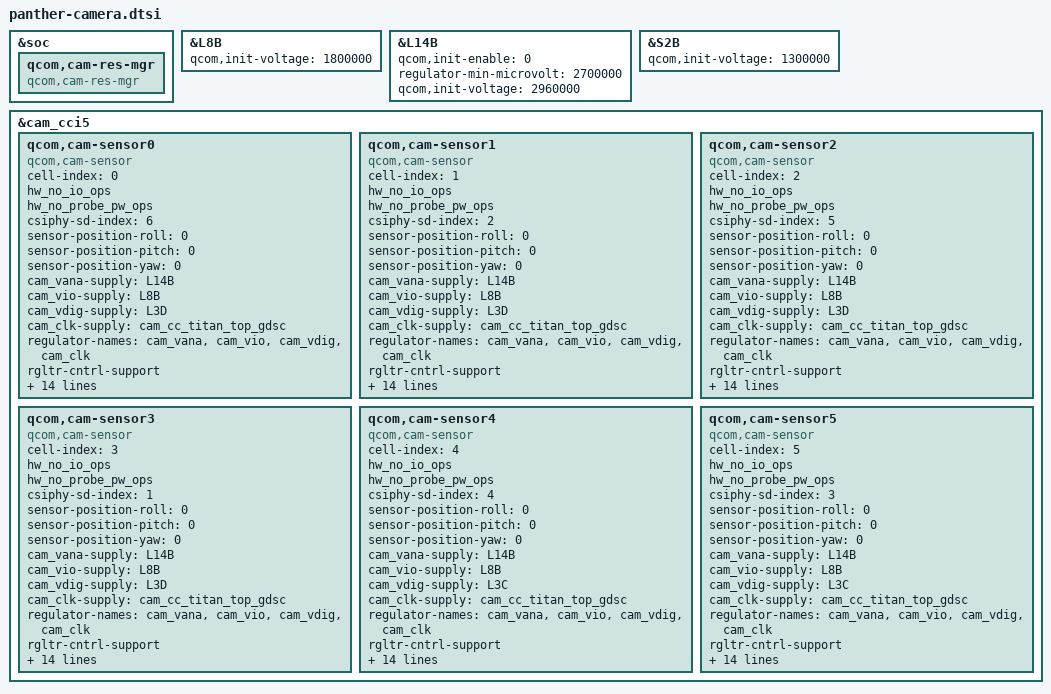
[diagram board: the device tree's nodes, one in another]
// SPDX-License-Identifier: GPL-2.0

#include <dt-bindings/camera/msm-camera.h>
#include <dt-bindings/clock/qcom,camcc-anorak.h>

&soc {
	qcom,cam-res-mgr {
		compatible = "qcom,cam-res-mgr";
		status = "ok";
	};
};

&L8B {
	qcom,init-voltage = <1800000>;
};

&L14B {
	qcom,init-enable = <0>;
	regulator-min-microvolt = <2700000>;
	qcom,init-voltage = <2960000>;
};

&S2B {
qcom,init-voltage = <1300000>;
};

&cam_cci5 {
	qcom,cam-sensor0 {
		/*
		 * CAMERA ID = 0
		 * name: CANYON2_FRONT_LEFT
		 * QCOM CSI PHY = 6
		 * QCOM MCLK = 1
		 */
		cell-index = <0>;
		hw_no_io_ops;
		hw_no_probe_pw_ops;
		compatible = "qcom,cam-sensor";
		csiphy-sd-index = <6>;
		sensor-position-roll = <0>;
		sensor-position-pitch = <0>;
		sensor-position-yaw = <0>;
		cam_vana-supply = <&L14B>;
		cam_vio-supply  = <&L8B>;
		cam_vdig-supply  = <&L3D>;
		cam_clk-supply  = <&cam_cc_titan_top_gdsc>;
		regulator-names = "cam_vana", "cam_vio", "cam_vdig",
			"cam_clk";
		rgltr-cntrl-support;
		rgltr-min-voltage = <2960000 1800000 1200000 0>;
		rgltr-max-voltage = <2960000 1800000 1200000 0>;
		rgltr-load-current = <80000 120000 120000 0>;
		gpio-no-mux = <0>;
		pinctrl-names = "cam_default", "cam_suspend";
		pinctrl-0 = <&cam_sensor_mclk1_active>;
		pinctrl-1 = <&cam_sensor_mclk1_suspend>;
		gpios = <&tlmm 21 0>;
		gpio-req-tbl-num = <0>;
		gpio-req-tbl-flags = <1>;
		gpio-req-tbl-label = "CAMIF_MCLK1";
		cci-master = <CCI_MASTER_0>;
		clocks = <&camcc CAM_CC_MCLK1_CLK>;
		clock-names = "cam_clk";
		clock-cntl-level = "nominal";
		clock-rates = <19200000>;
		status = "ok";
	};

	qcom,cam-sensor1 {
		/*
		 * CAMERA ID = 1
		 * name: CANYON2_FRONT_RIGHT
		 * QCOM CSI PHY = 2
		 * QCOM MCLK = 5
		 */
		cell-index = <1>;
		hw_no_io_ops;
		hw_no_probe_pw_ops;
		compatible = "qcom,cam-sensor";
		csiphy-sd-index = <2>;
		sensor-position-roll = <0>;
		sensor-position-pitch = <0>;
		sensor-position-yaw = <0>;
		cam_vana-supply = <&L14B>;
		cam_vio-supply  = <&L8B>;
		cam_vdig-supply  = <&L3D>;
		cam_clk-supply  = <&cam_cc_titan_top_gdsc>;
		regulator-names = "cam_vana", "cam_vio", "cam_vdig",
			"cam_clk";
		rgltr-cntrl-support;
		rgltr-min-voltage = <2960000 1800000 1200000 0>;
		rgltr-max-voltage = <2960000 1800000 1200000 0>;
		rgltr-load-current = <80000 120000 120000 0>;
		gpio-no-mux = <0>;
		pinctrl-names = "cam_default", "cam_suspend";
		pinctrl-0 = <&cam_sensor_mclk5_active>;
		pinctrl-1 = <&cam_sensor_mclk5_suspend>;
		gpios = <&tlmm 25 0>;
		gpio-req-tbl-num = <0>;
		gpio-req-tbl-flags = <1>;
		gpio-req-tbl-label = "CAMIF_MCLK5";
		cci-master = <CCI_MASTER_0>;
		clocks = <&camcc CAM_CC_MCLK5_CLK>;
		clock-names = "cam_clk";
		clock-cntl-level = "nominal";
		clock-rates = <19200000>;
		status = "ok";
	};

	qcom,cam-sensor2 {
		/*
		 * CAMERA ID = 2
		 * name: CANYON2_SIDE_LEFT
		 * QCOM CSI PHY = 5
		 * QCOM MCLK = 2
		 */
		cell-index = <2>;
		hw_no_io_ops;
		hw_no_probe_pw_ops;
		compatible = "qcom,cam-sensor";
		csiphy-sd-index = <5>;
		sensor-position-roll = <0>;
		sensor-position-pitch = <0>;
		sensor-position-yaw = <0>;
		cam_vana-supply = <&L14B>;
		cam_vio-supply  = <&L8B>;
		cam_vdig-supply  = <&L3D>;
		cam_clk-supply  = <&cam_cc_titan_top_gdsc>;
		regulator-names = "cam_vana", "cam_vio", "cam_vdig",
			"cam_clk";
		rgltr-cntrl-support;
		rgltr-min-voltage = <2960000 1800000 1200000 0>;
		rgltr-max-voltage = <2960000 1800000 1200000 0>;
		rgltr-load-current = <80000 120000 120000 0>;
		gpio-no-mux = <0>;
		pinctrl-names = "cam_default", "cam_suspend";
		pinctrl-0 = <&cam_sensor_mclk2_active>;
		pinctrl-1 = <&cam_sensor_mclk2_suspend>;
		gpios = <&tlmm 22 0>;
		gpio-req-tbl-num = <0>;
		gpio-req-tbl-flags = <1>;
		gpio-req-tbl-label = "CAMIF_MCLK2";
		cci-master = <CCI_MASTER_0>;
		clocks = <&camcc CAM_CC_MCLK2_CLK>;
		clock-names = "cam_clk";
		clock-cntl-level = "nominal";
		clock-rates = <19200000>;
		status = "ok";
	};

	qcom,cam-sensor3 {
		/*
		 * CAMERA ID = 3
		 * name: CANYON2_SIDE_RIGHT
		 * QCOM CSI PHY = 1
		 * QCOM MCLK = 3
		 */
		cell-index = <3>;
		hw_no_io_ops;
		hw_no_probe_pw_ops;
		compatible = "qcom,cam-sensor";
		csiphy-sd-index = <1>;
		sensor-position-roll = <0>;
		sensor-position-pitch = <0>;
		sensor-position-yaw = <0>;
		cam_vana-supply = <&L14B>;
		cam_vio-supply  = <&L8B>;
		cam_vdig-supply  = <&L3D>;
		cam_clk-supply  = <&cam_cc_titan_top_gdsc>;
		regulator-names = "cam_vana", "cam_vio", "cam_vdig",
			"cam_clk";
		rgltr-cntrl-support;
		rgltr-min-voltage = <2960000 1800000 1200000 0>;
		rgltr-max-voltage = <2960000 1800000 1200000 0>;
		rgltr-load-current = <80000 120000 120000 0>;
		gpio-no-mux = <0>;
		pinctrl-names = "cam_default", "cam_suspend";
		pinctrl-0 = <&cam_sensor_mclk3_active>;
		pinctrl-1 = <&cam_sensor_mclk3_suspend>;
		gpios = <&tlmm 23 0>;
		gpio-req-tbl-num = <0>;
		gpio-req-tbl-flags = <1>;
		gpio-req-tbl-label = "CAMIF_MCLK3";
		cci-master = <CCI_MASTER_0>;
		clocks = <&camcc CAM_CC_MCLK3_CLK>;
		clock-names = "cam_clk";
		clock-cntl-level = "nominal";
		clock-rates = <19200000>;
		status = "ok";
	};

	qcom,cam-sensor4 {
		/*
		 * CAMERA ID = 4
		 * name: JACKSON_LEFT
		 * QCOM CSI PHY = 4
		 * QCOM MCLK = 0
		 */
		cell-index = <4>;
		hw_no_io_ops;
		hw_no_probe_pw_ops;
		compatible = "qcom,cam-sensor";
		csiphy-sd-index = <4>;
		sensor-position-roll = <0>;
		sensor-position-pitch = <0>;
		sensor-position-yaw = <0>;
		cam_vana-supply = <&L14B>;
		cam_vio-supply  = <&L8B>;
		cam_vdig-supply  = <&L3C>;
		cam_clk-supply  = <&cam_cc_titan_top_gdsc>;
		regulator-names = "cam_vana", "cam_vio", "cam_vdig",
			"cam_clk";
		rgltr-cntrl-support;
		rgltr-min-voltage = <2960000 1800000 1050000 0>;
		rgltr-max-voltage = <2960000 1800000 1050000 0>;
		rgltr-load-current = <80000 120000 120000 0>;
		gpio-no-mux = <0>;
		pinctrl-names = "cam_default", "cam_suspend";
		pinctrl-0 = <&cam_sensor_mclk0_active>;
		pinctrl-1 = <&cam_sensor_mclk0_suspend>;
		gpios = <&tlmm 20 0>;
		gpio-req-tbl-num = <0>;
		gpio-req-tbl-flags = <1>;
		gpio-req-tbl-label = "CAMIF_MCLK0";
		cci-master = <CCI_MASTER_0>;
		clocks = <&camcc CAM_CC_MCLK0_CLK>;
		clock-names = "cam_clk";
		clock-cntl-level = "nominal";
		clock-rates = <19200000>;
		status = "ok";
	};

	qcom,cam-sensor5 {
		/*
		 * CAMERA ID = 5
		 * name: JACKSON_RIGHT
		 * QCOM CSI PHY = 3
		 * QCOM MCLK = 6
		 */
		cell-index = <5>;
		hw_no_io_ops;
		hw_no_probe_pw_ops;
		compatible = "qcom,cam-sensor";
		csiphy-sd-index = <3>;
		sensor-position-roll = <0>;
		sensor-position-pitch = <0>;
		sensor-position-yaw = <0>;
		cam_vana-supply = <&L14B>;
		cam_vio-supply  = <&L8B>;
		cam_vdig-supply  = <&L3C>;
		cam_clk-supply  = <&cam_cc_titan_top_gdsc>;
		regulator-names = "cam_vana", "cam_vio", "cam_vdig",
			"cam_clk";
		rgltr-cntrl-support;
		rgltr-min-voltage = <2960000 1800000 1050000 0>;
		rgltr-max-voltage = <2960000 1800000 1050000 0>;
		rgltr-load-current = <80000 120000 120000 0>;
		gpio-no-mux = <0>;
		pinctrl-names = "cam_default", "cam_suspend";
		pinctrl-0 = <&cam_sensor_mclk6_active>;
		pinctrl-1 = <&cam_sensor_mclk6_suspend>;
		gpios = <&tlmm 26 0>;
		gpio-req-tbl-num = <0>;
		gpio-req-tbl-flags = <1>;
		gpio-req-tbl-label = "CAMIF_MCLK6";
		cci-master = <CCI_MASTER_0>;
		clocks = <&camcc CAM_CC_MCLK6_CLK>;
		clock-names = "cam_clk";
		clock-cntl-level = "nominal";
		clock-rates = <19200000>;
		status = "ok";
	};
};
